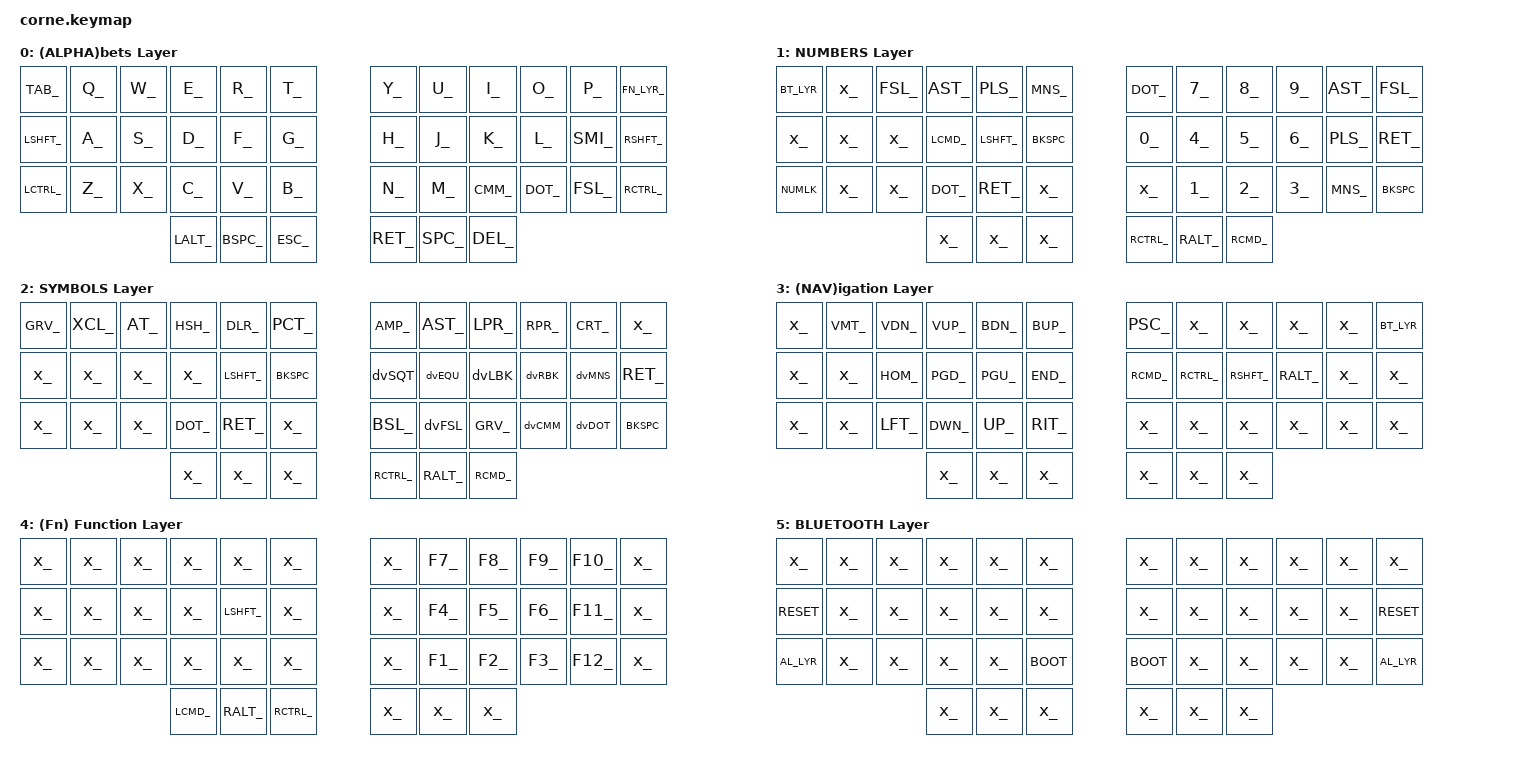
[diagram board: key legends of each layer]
/*
 * Copyright (c) 2020 The ZMK Contributors
 *
 * SPDX-License-Identifier: MIT
 */

#include <behaviors.dtsi>
#include <dt-bindings/zmk/keys.h>
#include <dt-bindings/zmk/bt.h>
#include <dt-bindings/zmk/reset.h>

// custom header imports.
#include "headers/keymap_aliases.h"

/ {
        behaviors {
					qmt: qmt_node {
						compatible = "zmk,behavior-hold-tap";
						flavor = "hold-preferred";
						tapping-term-ms = <200>;
						quick-tap-ms = <200>;
						#binding-cells = <2>;
						bindings = <&kp>, <&kp>;
					};

					qlt: qlt_node {
						compatible = "zmk,behavior-hold-tap";
						flavor = "tap-preferred";
						tapping-term-ms = <200>;
						quick-tap-ms = <200>;
						#binding-cells = <2>;
						bindings = <&mo>, <&kp>;
					};
				};

        keymap {
                compatible = "zmk,keymap";

                ALPHA {
// ╭──────┬─────┬─────┬─────┬─────┬─────╮                  ╭─────┬─────┬─────┬─────┬─────┬──────╮
// | TAB  |  Q  |  W  |  E  |  R  |  T  |                  |  Y  |  U  |  I  |  O  |  P  |FN_LYR|
// | SHFT |  A  |  S  |  D  |  F  |  G  |                  |  H  |  J  |  K  |  L  |  ;  | SHFT |
// | CTRL |  Z  |  X  |  C  |  V  |  B  |                  |  N  |  M  |  ,  |  .  |  /  | CTRL |
// ╰──────┴─────┴─────┴─────┴─────┴─────╯───────╮  ╭───────╰─────┴─────┴─────┴─────┴─────┴──────╯
//                      |  ALT  | BKSPC |  ESC  |  | ENTER | SPACE |  DEL  |
//                      ╰───────┴───────┴───────╯  ╰───────┴───────┴───────╯
//      TAB:  (hold)=FUNCTION layer
// (L) CTRL: (press)=CAPSLOCK.
//     BSPC:  (hold)=SYMBOL layer.
//      ESC:  (hold)=NUMBER layer.
//    ENTER:  (hold)=NAVIGATION layer.
//      DEL:  (hold)=Command/WIN key.
//   FN_LYR:  (hold)=Function Layer; (tap)=NOTHING.

                        display-name = "(ALPHA)bets Layer";
                        bindings = <
    _TAB_   _Q_   _W_   _E_   _R_   _T_                      _Y_   _U_   _I_   _O_    _P_   FN_LYR_
   _LSHFT_  _A_   _S_   _D_   _F_   _G_                      _H_   _J_   _K_   _L_   _SMI_  _RSHFT_
   LCTRL_  _Z_   _X_   _C_   _V_   _B_                      _N_   _M_  _CMM_ _DOT_  _FSL_  _RCTRL_
                         _LALT_   BSPC_   ESC_        RET_  _SPC_   DEL_
                        >;
                };

                NUMBERS {
// ╭──────┬─────┬─────┬─────┬─────┬─────╮                  ╭─────┬─────┬─────┬─────┬─────┬──────╮
// |BT_LYR|     |  /  |  *  |  +  |  -  |                  |  .  |  7  |  8  |  9  |  *  |  /   |
// |      |     |     | CMD |SHIFT|BKSPC|                  |  0  |  4  |  5  |  6  |  +  |ENTER |
// |NUMLCK|     |     |  .  |ENTER|     |                  |     |  1  |  2  |  3  |  -  |BKSPC |
// ╰──────┴─────┴─────┴─────┴─────┴─────╯───────╮  ╭───────╰─────┴─────┴─────┴─────┴─────┴──────╯
//                      |       |       |       |  |  CTRL |  ALT  |  CMD  |
//                      ╰───────┴───────┴───────╯  ╰───────┴───────┴───────╯

                        display-name = "NUMBERS Layer";
                        bindings = <
   BT_LYR   _x_  _FSL_ _AST_ _PLS_   _MNS_                 _DOT_  _7_   _8_   _9_   _AST_  _FSL_
     _x_    _x_   _x_ _LCMD_ _LSHFT_  BKSPC                  _0_   _4_   _5_   _6_   _PLS_  _RET_
   NUMLK    _x_   _x_  _DOT_ _RET_    _x_                   _x_   _1_   _2_   _3_   _MNS_  BKSPC
                          _x_     _x_     _x_       _RCTRL_  _RALT_  _RCMD_
                        >;
                };

                SYMBOLS {
                        display-name = "SYMBOLS Layer";
// ╭──────┬─────┬─────┬─────┬─────┬─────╮                  ╭─────┬─────┬─────┬─────┬─────┬──────╮
// |  ~   |  !  |  @  |  #  |  $  |  %  |                  |  &  |  *  |  (  |  )  |  ^  |      |
// |      |     |     |     |SHIFT|BKSPC|                  |  '  |  =  |  {  |  }  |  -  |ENTER |
// |      |     |     |  .  |ENTER|     |                  |  \  |  /  |  ~  |  ,  |  .  |BKSPC |
// ╰──────┴─────┴─────┴─────┴─────┴─────╯───────╮  ╭───────╰─────┴─────┴─────┴─────┴─────┴──────╯
//                      |       |       |       |  |  CTRL |  ALT  |  CMD  |
//                      ╰───────┴───────┴───────╯  ╰───────┴───────┴───────╯
                        bindings = <
    _GRV_  _XCL_  _AT_ _HSH_ _DLR_  _PCT_                   _AMP_ _AST_ _LPR_ _RPR_ _CRT_   _x_
     _x_    _x_   _x_   _x_ _LSHFT_ BKSPC                   dvSQT dvEQU dvLBK dvRBK dvMNS  _RET_
     _x_    _x_   _x_  _DOT_ _RET_  _x_                     _BSL_ dvFSL _GRV_ dvCMM dvDOT  BKSPC
                           _x_     _x_     _x_      _RCTRL_  _RALT_  _RCMD_
                        >;
                };

                NAV {
                        display-name = "(NAV)igation Layer";
// ╭──────┬─────┬─────┬─────┬─────┬─────╮                  ╭─────┬─────┬─────┬─────┬─────┬──────╮
// |      |Mute |Vol- |Vol+ | Br-   Br+ |                  |_PSC_|     |     |     |     |BT_LYR|
// |      |     |HOME |PGDN |PGUP | END |                  | CMD |CTRL |SHIFT| ALT |     |      |
// |      |     |LEFT |DOWN | UP  |RIGHT|                  |     |     |     |     |     |      |
// ╰──────┴─────┴─────┴─────┴─────┴─────╯───────╮  ╭───────╰─────┴─────┴─────┴─────┴─────┴──────╯
//                      |       |       |       |  |       |       |       |
//                      ╰───────┴───────┴───────╯  ╰───────┴───────┴───────╯
                        bindings = <
     _x_   _VMT_ _VDN_ _VUP_ _BDN_  _BUP_                   _PSC_  _x_   _x_   _x_   _x_  BT_LYR
     _x_    _x_  _HOM_ _PGD_ _PGU_  _END_                 _RCMD_ _RCTRL_ _RSHFT_ _RALT_ _x_ _x_
     _x_    _x_  _LFT_ _DWN_  _UP_  _RIT_                    _x_   _x_   _x_   _x_   _x_    _x_
                           _x_     _x_     _x_        _x_     _x_     _x_
                        >;
                };

                Fn {
// ╭──────┬─────┬─────┬─────┬─────┬─────╮                  ╭─────┬─────┬─────┬─────┬─────┬──────╮
// |      |     |     |     |     |     |                  |     | F7  | F8  | F9  | F10 |      |
// |      |     |     |     |SHIFT|     |                  |     | F4  | F5  | F6  | F11 |      |
// |      |     |     |     |     |     |                  |     | F1  | F2  | F3  | F12 |      |
// ╰──────┴─────┴─────┴─────┴─────┴─────╯───────╮  ╭───────╰─────┴─────┴─────┴─────┴─────┴──────╯
//                      |  CMD  |  ALT  |  CTRL |  |       |       |       |
//                      ╰───────┴───────┴───────╯  ╰───────┴───────┴───────╯

                        display-name = "(Fn) Function Layer";
                        bindings = <
     _x_    _x_   _x_   _x_   _x_     _x_                   _x_   _F7_  _F8_  _F9_  _F10_   _x_
     _x_    _x_   _x_   _x_ _LSHFT_   _x_                   _x_   _F4_  _F5_  _F6_  _F11_   _x_
     _x_    _x_   _x_   _x_   _x_     _x_                   _x_   _F1_  _F2_  _F3_  _F12_   _x_
                        _LCMD_  _RALT_  _RCTRL_        _x_     _x_    _x_
                        >;
                };

                BLUETOOTH {
// ╭──────┬─────┬─────┬─────┬─────┬─────╮                  ╭─────┬─────┬─────┬─────┬─────┬──────╮
// |BT CLR|BT 1 |BT 1 |BT 2 |BT 3 |BT 4 |                  |     |     |     |     |     |      |
// |RESET |     |     |     |     |     |                  |     |     |     |     |     |RESET |
// |AL_LYR|     |     |     |     |BOOT |                  |BOOT |     |     |     |     |AL_LYR|
// ╰──────┴─────┴─────┴─────┴─────┴─────╯───────╮  ╭───────╰─────┴─────┴─────┴─────┴─────┴──────╯
//                      |       |       |       |  |       |       |       |
//                      ╰───────┴───────┴───────╯  ╰───────┴───────┴───────╯

                        display-name = "BLUETOOTH Layer";
                        bindings = <
     _x_    _x_   _x_   _x_   _x_   _x_                     _x_    _x_   _x_   _x_   _x_   _x_ 
    RESET   _x_   _x_   _x_   _x_   _x_                     _x_    _x_   _x_   _x_   _x_  RESET
    AL_LYR  _x_   _x_   _x_   _x_  BOOT                     BOOT   _x_   _x_   _x_   _x_  AL_LYR
                          _x_    _x_     _x_            _x_    _x_    _x_  
                        >;
                };
        };
};
